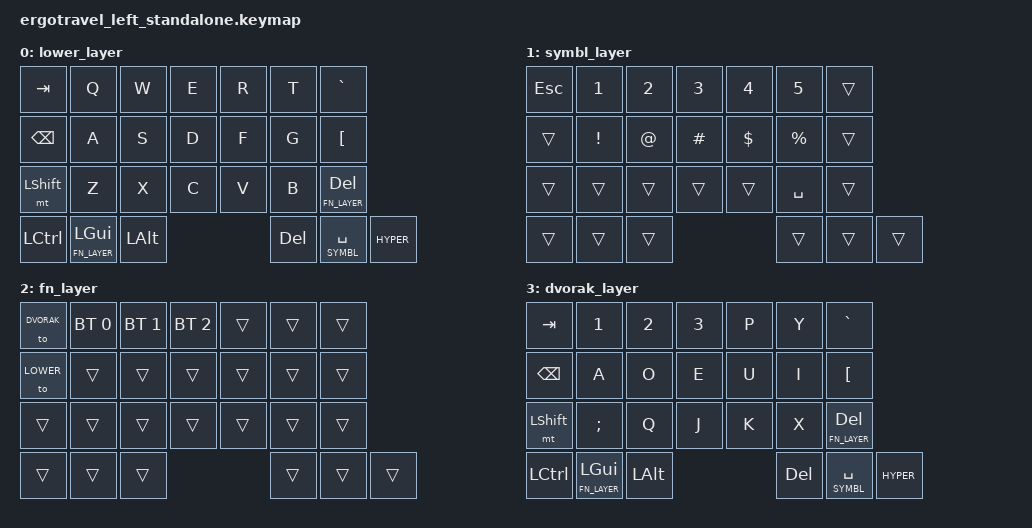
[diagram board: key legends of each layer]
/*
 * Copyright (c) 2020 The ZMK Contributors
 *
 * SPDX-License-Identifier: MIT
 */

#include <behaviors.dtsi>
#include <dt-bindings/zmk/keys.h>
#include <dt-bindings/zmk/bt.h>
#include <dt-bindings/zmk/ext_power.h>

#define LOWER 0
#define SYMBL 1
#define FN_LAYER 2
#define DVORAK 3
#define HYPER LS(LC(LGUI))
&lt { tapping_term_ms = <300>; };
&mt { tapping_term_ms = <300>; };
&sl { release-after-ms = <2000>; };

/ { keymap { compatible = "zmk,keymap";

lower_layer { bindings = <
&kp TAB   &kp Q     &kp W      &kp E    &kp R    &kp T     &kp GRAVE
&kp BKSP  &kp A     &kp S      &kp D    &kp F    &kp G     &kp LBKT
&mt LSHFT &kp Z     &kp X      &kp C    &kp V    &kp B     &lt FN_LAYER DEL
&kp LCTL  &lt FN_LAYER LGUI    &kp LALT &kp DEL  &lt SYMBL SPACE &kp HYPER
>; };

symbl_layer { bindings = <
&kp ESC     &kp N1   &kp N2  &kp N3   &kp N4   &kp N5    &trans
&trans      &kp EXCL &kp AT  &kp HASH &kp DLLR &kp PRCNT &trans
&trans      &trans   &trans  &trans   &trans   &kp SPACE &trans
&trans      &trans   &trans  &trans   &trans   &trans
>; };

fn_layer { bindings = <
&to DVORAK &bt BT_SEL 0 &bt BT_SEL 1 &bt BT_SEL 2 &trans  &trans  &trans
&to LOWER &trans &trans &trans &trans &trans &trans
&trans &trans &trans &trans &trans &trans &trans
&trans &trans &trans &trans &trans &trans
>; };

dvorak_layer { bindings = <
&kp TAB   &kp N1    &kp N2     &kp N3   &kp P    &kp Y     &kp GRAVE
&kp BKSP  &kp A     &kp O      &kp E    &kp U    &kp I     &kp LBKT
&mt LSHFT &kp SEMI  &kp Q      &kp J    &kp K    &kp X     &lt FN_LAYER DEL
&kp LCTL  &lt FN_LAYER LGUI    &kp LALT &kp DEL  &lt SYMBL SPACE &kp HYPER
>; };

}; };
